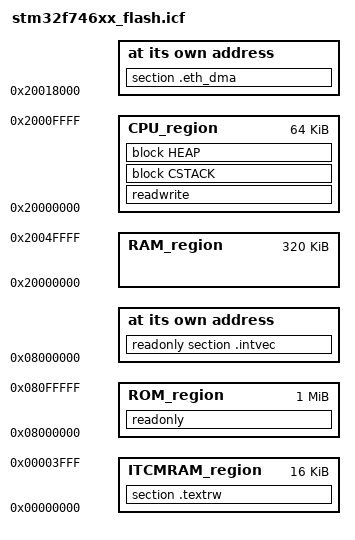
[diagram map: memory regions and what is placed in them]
/*###ICF### Section handled by ICF editor, don't touch! ****/
/*-Editor annotation file-*/
/* IcfEditorFile="$TOOLKIT_DIR$\config\ide\IcfEditor\cortex_v1_0.xml" */
/*-Specials-*/
define symbol __ICFEDIT_intvec_start__ = 0x08000000;
/*-Memory Regions-*/
define symbol __ICFEDIT_region_ROM_start__     = 0x08000000;
define symbol __ICFEDIT_region_ROM_end__       = 0x080FFFFF;
define symbol __ICFEDIT_region_RAM_start__     = 0x20000000;
define symbol __ICFEDIT_region_RAM_end__       = 0x2004FFFF;
define symbol __ICFEDIT_region_ITCMRAM_start__ = 0x00000000;
define symbol __ICFEDIT_region_ITCMRAM_end__   = 0x00003FFF;
/*-Sizes-*/
define symbol __ICFEDIT_size_cstack__ = 0x1000;
define symbol __ICFEDIT_size_heap__   = 0x200;
/**** End of ICF editor section. ###ICF###*/


define memory mem with size = 4G;
define region ROM_region      = mem:[from __ICFEDIT_region_ROM_start__   to __ICFEDIT_region_ROM_end__];
define region RAM_region      = mem:[from __ICFEDIT_region_RAM_start__   to __ICFEDIT_region_RAM_end__];
/* Keep CPU snapshots, timing state and C stack in the original DTCM bank.
 * Ethernet OWN descriptors/packet bytes alone use explicit SRAM1. */
define region CPU_region = mem:[from 0x20000000 to 0x2000FFFF];
define region ITCMRAM_region  = mem:[from __ICFEDIT_region_ITCMRAM_start__ to __ICFEDIT_region_ITCMRAM_end__];

define block CSTACK    with alignment = 8, size = __ICFEDIT_size_cstack__   { };
define block HEAP      with alignment = 8, size = __ICFEDIT_size_heap__     { };

initialize by copy { readwrite };
do not initialize  { section .noinit };

place at address mem:__ICFEDIT_intvec_start__ { readonly section .intvec };

/* Ethernet DMA: SRAM1 0x20018000.., ADC remains at 0x20010000. */
do not initialize { section .eth_dma };
place at address mem:0x20018000 { section .eth_dma };

place in ROM_region   { readonly };
place in CPU_region   { readwrite,
                        block CSTACK, block HEAP };
/* GEAR3/GEAR4 fast ISR body: __ramfunc code (.textrw) is copied from flash
 * into ITCM at startup so every ISR runs at 0 wait states, independent of
 * the flash I-Cache state. Thresholds are unchanged; only fetch speed is.
 * Same pattern as IAR's own config\linker\AnalogDevices\ADuCM4050.icf, which
 * places section .textrw in the instruction RAM after the generic rules. */
place in ITCMRAM_region { section .textrw };
